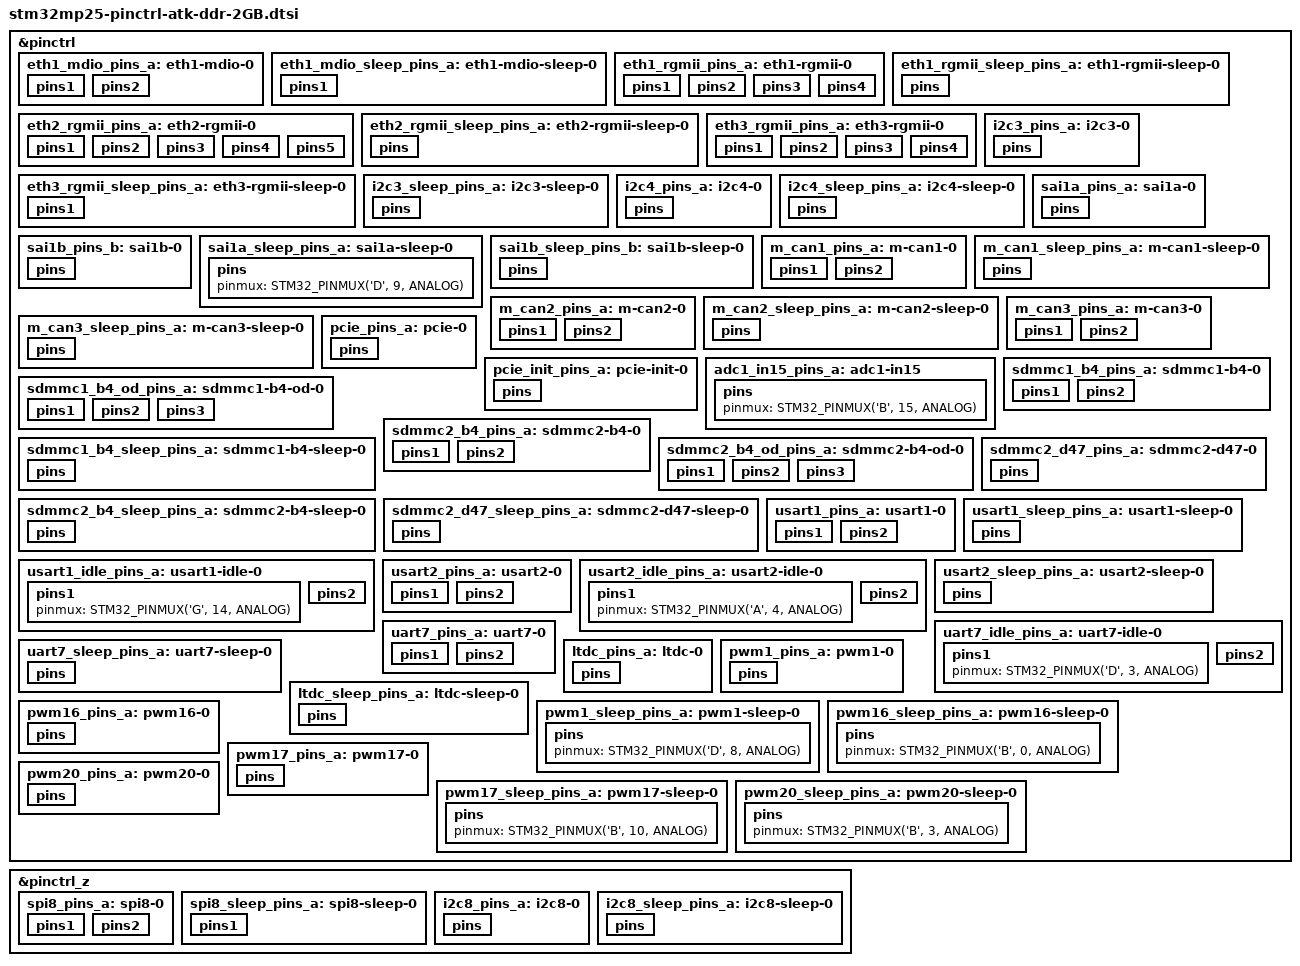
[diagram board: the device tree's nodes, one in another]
// SPDX-License-Identifier: (GPL-2.0-or-later OR BSD-3-Clause)
/*
 * Copyright (C) ALIENTEK - All Rights Reserved
 */
#include <dt-bindings/pinctrl/stm32-pinfunc.h>

&pinctrl {
	eth1_mdio_pins_a: eth1-mdio-0 {
		pins1 {
			pinmux = <STM32_PINMUX('F', 0, AF10)>; /* ETH_MDC */
			bias-disable;
			drive-push-pull;
			slew-rate = <2>;
		};
		pins2 {
			pinmux = <STM32_PINMUX('F', 2, AF10)>; /* ETH_MDIO */
			bias-disable;
			drive-push-pull;
			slew-rate = <0>;
		};
	};

	eth1_mdio_sleep_pins_a: eth1-mdio-sleep-0 {
		pins1 {
			pinmux = <STM32_PINMUX('F', 0, ANALOG)>, /* ETH_MDC */
				 <STM32_PINMUX('F', 2, ANALOG)>; /* ETH_MDIO */
		};
	};

	eth1_rgmii_pins_a: eth1-rgmii-0 {
		pins1 {
			pinmux = <STM32_PINMUX('A', 15, AF10)>, /* ETH_RGMII_TXD0 */
				 <STM32_PINMUX('C', 1, AF10)>, /* ETH_RGMII_TXD1 */
				 <STM32_PINMUX('H', 10, AF10)>, /* ETH_RGMII_TXD2 */
				 <STM32_PINMUX('H', 11, AF10)>, /* ETH_RGMII_TXD3 */
				 <STM32_PINMUX('A', 13, AF10)>; /* ETH_RGMII_TX_CTL */
			bias-disable;
			drive-push-pull;
			slew-rate = <3>;
			st,io-retime = <1>;
			st,io-clk-edge = <1>;
		};
		pins2 {
			pinmux = <STM32_PINMUX('H', 9, AF10)>, /* ETH_RGMII_CLK125 */
				 <STM32_PINMUX('C', 0, AF12)>; /* ETH_RGMII_GTX_CLK */
			bias-disable;
			drive-push-pull;
			slew-rate = <3>;
		};
		pins3 {
			pinmux = <STM32_PINMUX('F', 1, AF10)>, /* ETH_RGMII_RXD0 */
				 <STM32_PINMUX('C', 2, AF10)>, /* ETH_RGMII_RXD1 */
				 <STM32_PINMUX('H', 12, AF10)>, /* ETH_RGMII_RXD2 */
				 <STM32_PINMUX('H', 13, AF10)>, /* ETH_RGMII_RXD3 */
				 <STM32_PINMUX('A', 11, AF10)>; /* ETH_RGMII_RX_CTL */
			bias-disable;
			st,io-retime = <1>;
			st,io-clk-edge = <1>;
		};
		pins4 {
			pinmux = <STM32_PINMUX('A', 14, AF10)>; /* ETH_RGMII_RX_CLK */
			bias-disable;
		};
	};

	eth1_rgmii_sleep_pins_a: eth1-rgmii-sleep-0 {
		pins {
			pinmux = <STM32_PINMUX('A', 15, ANALOG)>, /* ETH_RGMII_TXD0 */
				 <STM32_PINMUX('C', 1, ANALOG)>, /* ETH_RGMII_TXD1 */
				 <STM32_PINMUX('H', 10, ANALOG)>, /* ETH_RGMII_TXD2 */
				 <STM32_PINMUX('H', 11, ANALOG)>, /* ETH_RGMII_TXD3 */
				 <STM32_PINMUX('A', 13, ANALOG)>, /* ETH_RGMII_TX_CTL */
				 <STM32_PINMUX('H', 9, ANALOG)>, /* ETH_RGMII_CLK125 */
				 <STM32_PINMUX('C', 0, ANALOG)>, /* ETH_RGMII_GTX_CLK */
				 <STM32_PINMUX('F', 1, ANALOG)>, /* ETH_RGMII_RXD0 */
				 <STM32_PINMUX('C', 2, ANALOG)>, /* ETH_RGMII_RXD1 */
				 <STM32_PINMUX('H', 12, ANALOG)>, /* ETH_RGMII_RXD2 */
				 <STM32_PINMUX('H', 13, ANALOG)>, /* ETH_RGMII_RXD3 */
				 <STM32_PINMUX('A', 11, ANALOG)>, /* ETH_RGMII_RX_CTL */
				 <STM32_PINMUX('A', 14, ANALOG)>; /* ETH_RGMII_RX_CLK */
		};
	};

	eth2_rgmii_pins_a: eth2-rgmii-0 {
		pins1 {
			pinmux = <STM32_PINMUX('C', 7, AF10)>, /* ETH_RGMII_TXD0 */
				 <STM32_PINMUX('C', 8, AF10)>, /* ETH_RGMII_TXD1 */
				 <STM32_PINMUX('C', 9, AF10)>, /* ETH_RGMII_TXD2 */
				 <STM32_PINMUX('C', 10, AF10)>, /* ETH_RGMII_TXD3 */
				 <STM32_PINMUX('C', 4, AF10)>; /* ETH_RGMII_TX_CTL */
			bias-disable;
			drive-push-pull;
			slew-rate = <3>;
			st,io-retime = <1>;
			st,io-clk-edge = <1>;
		};
		pins2 {
			pinmux = <STM32_PINMUX('F', 8, AF10)>, /* ETH_RGMII_CLK125 */
				 <STM32_PINMUX('F', 7, AF10)>, /* ETH_RGMII_GTX_CLK */
				 <STM32_PINMUX('C', 6, AF10)>; /* ETH_MDC */
			bias-disable;
			drive-push-pull;
			slew-rate = <3>;
		};
		pins3 {
			pinmux = <STM32_PINMUX('C', 5, AF10)>; /* ETH_MDIO */
			bias-disable;
			drive-push-pull;
			slew-rate = <0>;
		};
		pins4 {
			pinmux = <STM32_PINMUX('G', 0, AF10)>, /* ETH_RGMII_RXD0 */
				 <STM32_PINMUX('C', 12, AF10)>, /* ETH_RGMII_RXD1 */
				 <STM32_PINMUX('F', 9, AF10)>, /* ETH_RGMII_RXD2 */
				 <STM32_PINMUX('C', 11, AF10)>, /* ETH_RGMII_RXD3 */
				 <STM32_PINMUX('C', 3, AF10)>; /* ETH_RGMII_RX_CTL */
			bias-disable;
			st,io-retime = <1>;
			st,io-clk-edge = <1>;
		};
		pins5 {
			pinmux = <STM32_PINMUX('F', 6, AF10)>; /* ETH_RGMII_RX_CLK */
			bias-disable;
		};
	};

	eth2_rgmii_sleep_pins_a: eth2-rgmii-sleep-0 {
		pins {
			pinmux = <STM32_PINMUX('C', 7, ANALOG)>, /* ETH_RGMII_TXD0 */
				 <STM32_PINMUX('C', 8, ANALOG)>, /* ETH_RGMII_TXD1 */
				 <STM32_PINMUX('C', 9, ANALOG)>, /* ETH_RGMII_TXD2 */
				 <STM32_PINMUX('C', 10, ANALOG)>, /* ETH_RGMII_TXD3 */
				 <STM32_PINMUX('C', 4, ANALOG)>, /* ETH_RGMII_TX_CTL */
				 <STM32_PINMUX('F', 8, ANALOG)>, /* ETH_RGMII_CLK125 */
				 <STM32_PINMUX('F', 7, ANALOG)>, /* ETH_RGMII_GTX_CLK */
				 <STM32_PINMUX('C', 6, ANALOG)>, /* ETH_MDC */
				 <STM32_PINMUX('C', 5, ANALOG)>, /* ETH_MDIO */
				 <STM32_PINMUX('G', 0, ANALOG)>, /* ETH_RGMII_RXD0 */
				 <STM32_PINMUX('C', 12, ANALOG)>, /* ETH_RGMII_RXD1 */
				 <STM32_PINMUX('F', 9, ANALOG)>, /* ETH_RGMII_RXD2 */
				 <STM32_PINMUX('C', 11, ANALOG)>, /* ETH_RGMII_RXD3 */
				 <STM32_PINMUX('C', 3, ANALOG)>, /* ETH_RGMII_RX_CTL */
				 <STM32_PINMUX('F', 6, ANALOG)>; /* ETH_RGMII_RX_CLK */
		};
	};

	eth3_rgmii_pins_a: eth3-rgmii-0 {
		pins1 {
			pinmux = <STM32_PINMUX('A', 6, AF14)>, /* ETH_RGMII_TXD0 */
				 <STM32_PINMUX('A', 7, AF14)>, /* ETH_RGMII_TXD1 */
				 <STM32_PINMUX('H', 6, AF14)>, /* ETH_RGMII_TXD2 */
				 <STM32_PINMUX('H', 3, AF14)>, /* ETH_RGMII_TXD3 */
				 <STM32_PINMUX('A', 3, AF14)>; /* ETH_RGMII_TX_CTL */
			bias-disable;
			drive-push-pull;
			slew-rate = <3>;
			st,io-retime = <1>;
			st,io-clk-edge = <1>;
		};
		pins2 {
			pinmux = <STM32_PINMUX('H', 2, AF14)>; /* ETH_RGMII_GTX_CLK */
			bias-disable;
			drive-push-pull;
			slew-rate = <3>;
			st,io-delay = <2>;
		};
		pins3 {
			pinmux = <STM32_PINMUX('A', 9, AF14)>, /* ETH_RGMII_RXD0 */
				 <STM32_PINMUX('A', 10, AF14)>, /* ETH_RGMII_RXD1 */
				 <STM32_PINMUX('H', 7, AF14)>, /* ETH_RGMII_RXD2 */
				 <STM32_PINMUX('H', 8, AF14)>, /* ETH_RGMII_RXD3 */
				 <STM32_PINMUX('A', 2, AF14)>; /* ETH_RGMII_RX_CTL */
			bias-disable;
			st,io-retime = <1>;
			st,io-clk-edge = <1>;
		};
		pins4 {
			pinmux = <STM32_PINMUX('A', 5, AF14)>; /* ETH_RGMII_RX_CLK */
			bias-disable;
		};
	};

	eth3_rgmii_sleep_pins_a: eth3-rgmii-sleep-0 {
		pins1 {
			pinmux = <STM32_PINMUX('A', 6, ANALOG)>, /* ETH_RGMII_TXD0 */
				 <STM32_PINMUX('A', 7, ANALOG)>, /* ETH_RGMII_TXD1 */
				 <STM32_PINMUX('H', 6, ANALOG)>, /* ETH_RGMII_TXD2 */
				 <STM32_PINMUX('H', 3, ANALOG)>, /* ETH_RGMII_TXD3 */
				 <STM32_PINMUX('A', 3, ANALOG)>, /* ETH_RGMII_TX_CTL */
				 <STM32_PINMUX('H', 2, ANALOG)>, /* ETH_RGMII_GTX_CLK */
				 <STM32_PINMUX('A', 9, ANALOG)>, /* ETH_RGMII_RXD0 */
				 <STM32_PINMUX('A', 10, ANALOG)>, /* ETH_RGMII_RXD1 */
				 <STM32_PINMUX('H', 7, ANALOG)>, /* ETH_RGMII_RXD2 */
				 <STM32_PINMUX('H', 8, ANALOG)>, /* ETH_RGMII_RXD3 */
				 <STM32_PINMUX('A', 2, ANALOG)>, /* ETH_RGMII_RX_CTL */
				 <STM32_PINMUX('A', 5, ANALOG)>; /* ETH_RGMII_RX_CLK */
		};
	};

	i2c3_pins_a: i2c3-0 {
		pins {
			pinmux = <STM32_PINMUX('G', 1, AF9)>, /* I2C3_SCL */
				 <STM32_PINMUX('G', 2, AF9)>; /* I2C3_SDA */
			bias-disable;
			drive-open-drain;
			slew-rate = <0>;
		};
	};

	i2c3_sleep_pins_a: i2c3-sleep-0 {
		pins {
			pinmux = <STM32_PINMUX('G', 1, ANALOG)>, /* I2C3_SCL */
				 <STM32_PINMUX('G', 2, ANALOG)>; /* I2C3_SDA */
		};
	};

	i2c4_pins_a: i2c4-0 {
		pins {
			pinmux = <STM32_PINMUX('D', 11, AF6)>, /* I2C4_SCL */
				 <STM32_PINMUX('D', 10, AF6)>; /* I2C4_SDA */
			bias-disable;
			drive-open-drain;
			slew-rate = <0>;
		};
	};

	i2c4_sleep_pins_a: i2c4-sleep-0 {
		pins {
			pinmux = <STM32_PINMUX('D', 11, ANALOG)>, /* I2C4_SCL */
				 <STM32_PINMUX('D', 10, ANALOG)>; /* I2C4_SDA */
		};
	};

	sai1a_pins_a: sai1a-0 {
		pins {
			pinmux = <STM32_PINMUX('D', 9, ANALOG)>; 	/* SAI1_SD_A */
			bias-disable;		
		};
	};

	sai1b_pins_b: sai1b-0 {
		pins {
			pinmux = <STM32_PINMUX('D', 7, AF4)>, 	/* SAI1_MCLK_B */
				 <STM32_PINMUX('D', 6, AF4)>, 		/* SAI1_SCK_B */
				 <STM32_PINMUX('D', 5, AF4)>, 		/* SAI1_FS_B */
				 <STM32_PINMUX('D', 4, AF4)>, 		/* SAI1_SD_B */
				 <STM32_PINMUX('D', 9, AF3)>; 		/* SAI1_SD_A */
			slew-rate = <0>;
			drive-push-pull;
			bias-disable;	
		};
	};

	sai1a_sleep_pins_a: sai1a-sleep-0 {
		pins {
			pinmux = <STM32_PINMUX('D', 9, ANALOG)>; 		/* SAI1_SD_A */
		};
	};

	sai1b_sleep_pins_b: sai1b-sleep-0 {
		pins {
			pinmux = <STM32_PINMUX('D', 7, ANALOG)>,	/* SAI1_MCLK_B */
				 <STM32_PINMUX('D', 6, ANALOG)>,		/* SAI1_SCK_B */
				 <STM32_PINMUX('D', 5, ANALOG)>,		/* SAI1_FS_B */
				 <STM32_PINMUX('D', 4, ANALOG)>;		/* SAI1_SD_B */
		};
	};
	
	m_can1_pins_a: m-can1-0 {
		pins1 {
			pinmux = <STM32_PINMUX('B', 9, AF7)>; /* CAN1_TX */
			slew-rate = <1>;
			drive-push-pull;
			bias-disable;
		};
		pins2 {
			pinmux = <STM32_PINMUX('B', 11, AF7)>; /* CAN1_RX */
			bias-disable;
		};
	};

	m_can1_sleep_pins_a: m-can1-sleep-0 {
		pins {
			pinmux = <STM32_PINMUX('B', 9, ANALOG)>, /* CAN1_TX */
				 <STM32_PINMUX('B', 11, ANALOG)>; /* CAN1_RX */
		};
	};

	m_can2_pins_a: m-can2-0 {
		pins1 {
			pinmux = <STM32_PINMUX('I', 9, AF4)>; /* CAN2_TX */
			slew-rate = <1>;
			drive-push-pull;
			bias-disable;
		};
		pins2 {
			pinmux = <STM32_PINMUX('I', 10, AF4)>; /* CAN2_RX */
			bias-disable;
		};
	};

	m_can2_sleep_pins_a: m-can2-sleep-0 {
		pins {
			pinmux = <STM32_PINMUX('I', 9, ANALOG)>, /* CAN2_TX */
				 <STM32_PINMUX('I', 10, ANALOG)>; /* CAN2_RX */
		};
	};

	m_can3_pins_a: m-can3-0 {
		pins1 {
			pinmux = <STM32_PINMUX('D', 2, AF9)>; /* CAN3_TX */
			slew-rate = <1>;
			drive-push-pull;
			bias-disable;
		};
		pins2 {
			pinmux = <STM32_PINMUX('D', 1, AF9)>; /* CAN3_RX */
			bias-disable;
		};
	};

	m_can3_sleep_pins_a: m-can3-sleep-0 {
		pins {
			pinmux = <STM32_PINMUX('D', 2, ANALOG)>, /* CAN3_TX */
				 <STM32_PINMUX('D', 1, ANALOG)>; /* CAN3_RX */
		};
	};
	
	pcie_pins_a: pcie-0 {
		pins {
			pinmux = <STM32_PINMUX('B', 8, AF4)>;
			bias-disable;
		};
	};

	pcie_init_pins_a: pcie-init-0 {
		pins {
			pinmux = <STM32_PINMUX('B', 8, GPIO)>;
			output-low;
		};
	};

	adc1_in15_pins_a: adc1-in15 {
		pins {
			pinmux = <STM32_PINMUX('B', 15, ANALOG)>;
		};
	};

	sdmmc1_b4_pins_a: sdmmc1-b4-0 {
		pins1 {
			pinmux = <STM32_PINMUX('E', 4, AF10)>, /* SDMMC1_D0 */
				 <STM32_PINMUX('E', 5, AF10)>, /* SDMMC1_D1 */
				 <STM32_PINMUX('E', 0, AF10)>, /* SDMMC1_D2 */
				 <STM32_PINMUX('E', 1, AF10)>, /* SDMMC1_D3 */
				 <STM32_PINMUX('E', 2, AF10)>; /* SDMMC1_CMD */
			slew-rate = <2>;
			drive-push-pull;
			bias-disable;
		};
		pins2 {
			pinmux = <STM32_PINMUX('E', 3, AF10)>; /* SDMMC1_CK */
			slew-rate = <3>;
			drive-push-pull;
			bias-disable;
		};
	};

	sdmmc1_b4_od_pins_a: sdmmc1-b4-od-0 {
		pins1 {
			pinmux = <STM32_PINMUX('E', 4, AF10)>, /* SDMMC1_D0 */
				 <STM32_PINMUX('E', 5, AF10)>, /* SDMMC1_D1 */
				 <STM32_PINMUX('E', 0, AF10)>, /* SDMMC1_D2 */
				 <STM32_PINMUX('E', 1, AF10)>; /* SDMMC1_D3 */
			slew-rate = <2>;
			drive-push-pull;
			bias-disable;
		};
		pins2 {
			pinmux = <STM32_PINMUX('E', 3, AF10)>; /* SDMMC1_CK */
			slew-rate = <3>;
			drive-push-pull;
			bias-disable;
		};
		pins3 {
			pinmux = <STM32_PINMUX('E', 2, AF10)>; /* SDMMC1_CMD */
			slew-rate = <2>;
			drive-open-drain;
			bias-disable;
		};
	};

	sdmmc1_b4_sleep_pins_a: sdmmc1-b4-sleep-0 {
		pins {
			pinmux = <STM32_PINMUX('E', 4, ANALOG)>, /* SDMMC1_D0 */
				 <STM32_PINMUX('E', 5, ANALOG)>, /* SDMMC1_D1 */
				 <STM32_PINMUX('E', 0, ANALOG)>, /* SDMMC1_D2 */
				 <STM32_PINMUX('E', 1, ANALOG)>, /* SDMMC1_D3 */
				 <STM32_PINMUX('E', 3, ANALOG)>, /* SDMMC1_CK */
				 <STM32_PINMUX('E', 2, ANALOG)>; /* SDMMC1_CMD */
		};
	};

	sdmmc2_b4_pins_a: sdmmc2-b4-0 {
		pins1 {
			pinmux = <STM32_PINMUX('E', 13, AF12)>, /* SDMMC2_D0 */
				 <STM32_PINMUX('E', 11, AF12)>, /* SDMMC2_D1 */
				 <STM32_PINMUX('E', 8, AF12)>, /* SDMMC2_D2 */
				 <STM32_PINMUX('E', 12, AF12)>, /* SDMMC2_D3 */
				 <STM32_PINMUX('E', 15, AF12)>; /* SDMMC2_CMD */
			slew-rate = <1>;
			drive-push-pull;
			bias-pull-up;
		};
		pins2 {
			pinmux = <STM32_PINMUX('E', 14, AF12)>; /* SDMMC2_CK */
			slew-rate = <2>;
			drive-push-pull;
			bias-pull-up;
		};
	};

	sdmmc2_b4_od_pins_a: sdmmc2-b4-od-0 {
		pins1 {
			pinmux = <STM32_PINMUX('E', 13, AF12)>, /* SDMMC2_D0 */
				 <STM32_PINMUX('E', 11, AF12)>, /* SDMMC2_D1 */
				 <STM32_PINMUX('E', 8, AF12)>, /* SDMMC2_D2 */
				 <STM32_PINMUX('E', 12, AF12)>; /* SDMMC2_D3 */
			slew-rate = <1>;
			drive-push-pull;
			bias-pull-up;
		};
		pins2 {
			pinmux = <STM32_PINMUX('E', 14, AF12)>; /* SDMMC2_CK */
			slew-rate = <2>;
			drive-push-pull;
			bias-pull-up;
		};
		pins3 {
			pinmux = <STM32_PINMUX('E', 15, AF12)>; /* SDMMC2_CMD */
			slew-rate = <1>;
			drive-open-drain;
			bias-pull-up;
		};
	};

	sdmmc2_b4_sleep_pins_a: sdmmc2-b4-sleep-0 {
		pins {
			pinmux = <STM32_PINMUX('E', 13, ANALOG)>, /* SDMMC2_D0 */
				 <STM32_PINMUX('E', 11, ANALOG)>, /* SDMMC2_D1 */
				 <STM32_PINMUX('E', 8, ANALOG)>, /* SDMMC2_D2 */
				 <STM32_PINMUX('E', 12, ANALOG)>, /* SDMMC2_D3 */
				 <STM32_PINMUX('E', 14, ANALOG)>, /* SDMMC2_CK */
				 <STM32_PINMUX('E', 15, ANALOG)>; /* SDMMC2_CMD */
		};
	};

	sdmmc2_d47_pins_a: sdmmc2-d47-0 {
		pins {
			pinmux = <STM32_PINMUX('E', 10, AF12)>, /* SDMMC2_D4 */
				 <STM32_PINMUX('E', 9, AF12)>, /* SDMMC2_D5 */
				 <STM32_PINMUX('E', 6, AF12)>, /* SDMMC2_D6 */
				 <STM32_PINMUX('E', 7, AF12)>; /* SDMMC2_D7 */
			slew-rate = <1>;
			drive-push-pull;
			bias-pull-up;
		};
	};

	sdmmc2_d47_sleep_pins_a: sdmmc2-d47-sleep-0 {
		pins {
			pinmux = <STM32_PINMUX('E', 10, ANALOG)>, /* SDMMC2_D4 */
				 <STM32_PINMUX('E', 9, ANALOG)>, /* SDMMC2_D5 */
				 <STM32_PINMUX('E', 6, ANALOG)>, /* SDMMC2_D6 */
				 <STM32_PINMUX('E', 7, ANALOG)>; /* SDMMC2_D7 */
		};
	};

	usart1_pins_a: usart1-0 {
		pins1 {
			pinmux = <STM32_PINMUX('G', 14, AF6)>; /* USART1_TX */
			bias-disable;
			drive-push-pull;
			slew-rate = <0>;
		};
		pins2 {
			pinmux = <STM32_PINMUX('G', 15, AF6)>; /* USART1_RX */
			bias-disable;
		};
	};

	usart1_idle_pins_a: usart1-idle-0 {
		pins1 {
			pinmux = <STM32_PINMUX('G', 14, ANALOG)>; /* USART1_TX */
		};
		pins2 {
			pinmux = <STM32_PINMUX('G', 15, AF6)>; /* USART1_RX */
			bias-disable;
		};
	};

	usart1_sleep_pins_a: usart1-sleep-0 {
		pins {
			pinmux = <STM32_PINMUX('G', 14, ANALOG)>, /* USART1_TX */
				 <STM32_PINMUX('G', 15, ANALOG)>; /* USART1_RX */
		};
	};

	usart2_pins_a: usart2-0 {
		pins1 {
			pinmux = <STM32_PINMUX('A', 4, AF6)>; /* USART2_TX */
			bias-disable;
			drive-push-pull;
			slew-rate = <0>;
		};
		pins2 {
			pinmux = <STM32_PINMUX('A', 8, AF8)>; /* USART2_RX */
			bias-pull-up;
		};
	};

	usart2_idle_pins_a: usart2-idle-0 {
		pins1 {
			pinmux = <STM32_PINMUX('A', 4, ANALOG)>; /* USART2_TX */
		};
		pins2 {
			pinmux = <STM32_PINMUX('A', 8, AF8)>; /* USART2_RX */
			bias-pull-up;
		};
	};

	usart2_sleep_pins_a: usart2-sleep-0 {
		pins {
			pinmux = <STM32_PINMUX('A', 4, ANALOG)>, /* USART2_TX */
				 <STM32_PINMUX('A', 8, ANALOG)>; /* USART2_RX */
		};
	};

	uart7_pins_a: uart7-0 {
		pins1 {
			pinmux = <STM32_PINMUX('D', 3, AF6)>; /* UART7_TX */
			bias-disable;
			drive-push-pull;
			slew-rate = <0>;
		};
		pins2 {
			pinmux = <STM32_PINMUX('D', 0, AF6)>; /* UART7_RX */
			bias-pull-up;
		};
	};

	uart7_idle_pins_a: uart7-idle-0 {
		pins1 {
			pinmux = <STM32_PINMUX('D', 3, ANALOG)>; /* UART7_TX */
		};
		pins2 {
			pinmux = <STM32_PINMUX('D', 0, AF6)>; /* UART7_RX */
			bias-pull-up;
		};
	};

	uart7_sleep_pins_a: uart7-sleep-0 {
		pins {
			pinmux = <STM32_PINMUX('D', 3, ANALOG)>, /* UART7_TX */
				 <STM32_PINMUX('D', 0, ANALOG)>; /* UART7_RX */
		};
	};

	ltdc_pins_a: ltdc-0 {
		pins {
			pinmux = <STM32_PINMUX('F', 12, AF13)>, /* LCD_CLK */
				 <STM32_PINMUX('I',  7, AF13)>, /* LCD_HSYNC */
				 <STM32_PINMUX('I',  6, AF13)>, /* LCD_VSYNC */
				 <STM32_PINMUX('I',  5, AF13)>, /* LCD_DE */
				 <STM32_PINMUX('F', 14, AF13)>, /* LCD_R3 */
				 <STM32_PINMUX('F', 15, AF13)>, /* LCD_R4 */
				 <STM32_PINMUX('G',  5, AF13)>, /* LCD_R5 */
				 <STM32_PINMUX('G',  6, AF13)>, /* LCD_R6 */
				 <STM32_PINMUX('G',  7, AF13)>, /* LCD_R7 */
				 <STM32_PINMUX('G',  8, AF13)>, /* LCD_G2 */
				 <STM32_PINMUX('G',  9, AF13)>, /* LCD_G3 */
				 <STM32_PINMUX('G', 10, AF13)>, /* LCD_G4 */
				 <STM32_PINMUX('G', 11, AF13)>, /* LCD_G5 */
				 <STM32_PINMUX('G', 12, AF13)>, /* LCD_G6 */
				 <STM32_PINMUX('G', 13, AF13)>, /* LCD_G7 */
				 <STM32_PINMUX('I',  0, AF13)>, /* LCD_B3 */
				 <STM32_PINMUX('I',  1, AF13)>, /* LCD_B4 */
				 <STM32_PINMUX('I',  2, AF13)>, /* LCD_B5 */
				 <STM32_PINMUX('I',  3, AF13)>, /* LCD_B6 */
				 <STM32_PINMUX('I',  4, AF13)>; /* LCD_B7 */
			bias-disable;
			drive-push-pull;
			slew-rate = <1>;
		};
	};

	ltdc_sleep_pins_a: ltdc-sleep-0 {
		pins {
			pinmux = <STM32_PINMUX('F', 12, ANALOG)>, /* LCD_CLK */
				 <STM32_PINMUX('I',  7, ANALOG)>, /* LCD_HSYNC */
				 <STM32_PINMUX('I',  6, ANALOG)>, /* LCD_VSYNC */
				 <STM32_PINMUX('I',  5, ANALOG)>, /* LCD_DE */
				 <STM32_PINMUX('F', 14, ANALOG)>, /* LCD_R3 */
				 <STM32_PINMUX('F', 15, ANALOG)>, /* LCD_R4 */
				 <STM32_PINMUX('G',  5, ANALOG)>, /* LCD_R5 */
				 <STM32_PINMUX('G',  6, ANALOG)>, /* LCD_R6 */
				 <STM32_PINMUX('G',  7, ANALOG)>, /* LCD_R7 */
				 <STM32_PINMUX('G',  8, ANALOG)>, /* LCD_G2 */
				 <STM32_PINMUX('G',  9, ANALOG)>, /* LCD_G3 */
				 <STM32_PINMUX('G', 10, ANALOG)>, /* LCD_G4 */
				 <STM32_PINMUX('G', 11, ANALOG)>, /* LCD_G5 */
				 <STM32_PINMUX('G', 12, ANALOG)>, /* LCD_G6 */
				 <STM32_PINMUX('G', 13, ANALOG)>, /* LCD_G7 */
				 <STM32_PINMUX('I',  0, ANALOG)>, /* LCD_B3 */
				 <STM32_PINMUX('I',  1, ANALOG)>, /* LCD_B4 */
				 <STM32_PINMUX('I',  2, ANALOG)>, /* LCD_B5 */
				 <STM32_PINMUX('I',  3, ANALOG)>, /* LCD_B6 */
				 <STM32_PINMUX('I',  4, ANALOG)>; /* LCD_B7 */
		};
	};

	pwm1_pins_a: pwm1-0 {
		pins {
			pinmux = <STM32_PINMUX('D', 8, AF8)>; /* TIM1_CH4 */
			bias-pull-down;
			drive-push-pull;
			slew-rate = <0>;
		};
	};

	pwm1_sleep_pins_a: pwm1-sleep-0 {
		pins {
			pinmux = <STM32_PINMUX('D', 8, ANALOG)>; /* TIM1_CH4 */
		};
	};

	pwm16_pins_a: pwm16-0 {
		pins {
			pinmux = <STM32_PINMUX('B', 0, AF7)>; /* TIM16_CH1 */
			bias-pull-down;
			drive-push-pull;
			slew-rate = <0>;
		};
	};

	pwm16_sleep_pins_a: pwm16-sleep-0 {
		pins {
			pinmux = <STM32_PINMUX('B', 0, ANALOG)>; /* TIM16_CH1 */
		};
	};

	pwm17_pins_a: pwm17-0 {
		pins {
			pinmux = <STM32_PINMUX('B', 10, AF7)>; /* TIM17_CH1N */
			bias-pull-down;
			drive-push-pull;
			slew-rate = <0>;
		};
	};

	pwm17_sleep_pins_a: pwm17-sleep-0 {
		pins {
			pinmux = <STM32_PINMUX('B', 10, ANALOG)>; /* TIM17_CH1N */
		};
	};

	pwm20_pins_a: pwm20-0 {
		pins {
			pinmux = <STM32_PINMUX('B', 3, AF8)>; /* TIM20_CH3 */
			bias-pull-down;
			drive-push-pull;
			slew-rate = <0>;
		};
	};

	pwm20_sleep_pins_a: pwm20-sleep-0 {
		pins {
			pinmux = <STM32_PINMUX('B', 3, ANALOG)>; /* TIM20_CH3 */
		};
	};		
};

&pinctrl_z {
	spi8_pins_a: spi8-0 {
		pins1 {
			pinmux = <STM32_PINMUX('Z', 2, AF3)>, /* SPI8_SCK */
				 <STM32_PINMUX('Z', 0, AF3)>; /* SPI8_MOSI */
			drive-push-pull;
			bias-disable;
			slew-rate = <1>;
		};
		pins2 {
			pinmux = <STM32_PINMUX('Z', 1, AF3)>; /* SPI8_MISO */
			bias-disable;
		};
	};

	spi8_sleep_pins_a: spi8-sleep-0 {
		pins1 {
			pinmux = <STM32_PINMUX('Z', 2, ANALOG)>, /* SPI8_SCK */
				 <STM32_PINMUX('Z', 0, ANALOG)>, /* SPI8_MOSI */
				 <STM32_PINMUX('Z', 1, ANALOG)>; /* SPI8_MISO */
		};
	};

	i2c8_pins_a: i2c8-0 {
		pins {
			pinmux = <STM32_PINMUX('Z', 4, AF8)>, /* I2C8_SCL */
				 <STM32_PINMUX('Z', 9, AF8)>; /* I2C8_SDA */
			bias-disable;
			drive-open-drain;
			slew-rate = <0>;
		};
	};

	i2c8_sleep_pins_a: i2c8-sleep-0 {
		pins {
			pinmux = <STM32_PINMUX('Z', 4, ANALOG)>, /* I2C8_SCL */
				 <STM32_PINMUX('Z', 9, ANALOG)>; /* I2C8_SDA */
		};
	};
};
